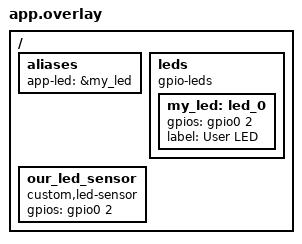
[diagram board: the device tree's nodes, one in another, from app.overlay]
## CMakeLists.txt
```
cmake_minimum_required(VERSION 3.20.0)

find_package(Zephyr REQUIRED)
project(my_zephyr_app)

target_sources(app PRIVATE src/main.c src/shell_cmds.c)
```

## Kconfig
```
# ============================================================================
# Application Kconfig — LED Subsystem
# ============================================================================
# This file defines the configuration space for the course application's
# LED heartbeat subsystem.  It demonstrates:
#   • A top-level menu entry
#   • A conditional block (`if … endif`)
#   • A `choice` with mutually-exclusive options
#   • An `int` symbol with `range`
#   • A `visible if` dependency on a sub-menu (modern Zephyr syntax)
#
# Zephyr's Kconfig auto-discovery will pick up this file because it lives in
# APPLICATION_SOURCE_DIR (i.e. the same directory as CMakeLists.txt).
# ============================================================================

menu "LED Subsystem"

# ---------------------------------------------------------------------------
# Master switch — everything below depends on this symbol.
# ---------------------------------------------------------------------------
config LED_SUBSYSTEM
	bool "Enable LED Subsystem"
	default y
	help
	  Enable the LED heartbeat subsystem.  When disabled, the LED pin is
	  left in its default (high-impedance) state and no GPIO activity occurs.

# ---------------------------------------------------------------------------
# All options below are visible only when the master switch is on.
# ---------------------------------------------------------------------------
if LED_SUBSYSTEM

# ---------------------------------------------------------------------------
# LED operating mode — mutually exclusive choices.
# ---------------------------------------------------------------------------
choice LED_MODE
	prompt "LED operating mode"
	default LED_MODE_BLINK
	help
	  Select how the LED behaves at run-time.

	  BLINK  – periodic toggle (heartbeat).
	  SOLID  – continuously driven ON.
	  OFF    – continuously driven OFF.

config LED_MODE_BLINK
	bool "Blink (heartbeat)"
	help
	  Toggle the LED at the period defined by APP_HEARTBEAT_PERIOD_MS.

config LED_MODE_SOLID
	bool "Solid ON"
	help
	  Drive the LED GPIO active-high and keep it on indefinitely.

config LED_MODE_OFF
	bool "Off"
	help
	  Drive the LED GPIO inactive and keep it off indefinitely.

endchoice

# ---------------------------------------------------------------------------
# Tuning options — only relevant when the mode is BLINK.
# ---------------------------------------------------------------------------
menu "Blink Tuning"
	visible if LED_MODE_BLINK

config APP_HEARTBEAT_PERIOD_MS
	int "Heartbeat period (ms)"
	default 500
	range 100 2000
	help
	  Blink period in milliseconds.  The value is clamped to the range
	  [100, 2000] to prevent eye-strain (too fast) or unresponsiveness
	  (too slow).

endmenu

# ---------------------------------------------------------------------------
# Diagnostics options — visible whenever the subsystem is enabled.
# ---------------------------------------------------------------------------
menu "Diagnostics"
	visible if LED_SUBSYSTEM

config LED_LOG_VERBOSE
	bool "Verbose LED logging"
	default n
	help
	  Log every LED state change to the console.  Useful for verifying that
	  the chosen mode and period are actually being applied at run-time.

endmenu

endif # LED_SUBSYSTEM

endmenu

# ---------------------------------------------------------------------------
# Pull in the full Zephyr Kconfig tree so that standard symbols (GPIO, LOG,
# etc.) are defined and can be referenced from prj.conf / defconfig files.
# ---------------------------------------------------------------------------
source "Kconfig.zephyr"
```

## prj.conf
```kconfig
# ============================================================================
# Project Configuration — Lecture 4 (Devicetree Overlay + Kconfig)
# ============================================================================
# This file overrides default values defined in the application Kconfig
# (app/Kconfig) and in Zephyr's own Kconfig tree.
# ============================================================================

# ---------------------------------------------------------------------------
# Zephyr base requirements
# ---------------------------------------------------------------------------
CONFIG_GPIO=y
CONFIG_LOG=y

# ---------------------------------------------------------------------------
# Heartbeat period (ms)
# Default in Kconfig is 500; range enforced: 100 .. 2000 ms.
# Change this value and rebuild to verify the LED blink speed changes.
# ---------------------------------------------------------------------------
CONFIG_APP_HEARTBEAT_PERIOD_MS=500
CONFIG_SENSOR=y
CONFIG_OUR_LED_SENSOR=y

# ---------------------------------------------------------------------------
# Shell subsystem (L7)
# ---------------------------------------------------------------------------
CONFIG_SHELL=y
CONFIG_SHELL_CMDS=y
CONFIG_SHELL_TAB=y
CONFIG_SHELL_TAB_AUTOCOMPLETION=y
CONFIG_SHELL_HISTORY=y
CONFIG_SHELL_LOG_BACKEND=y
CONFIG_SHELL_BACKEND_SERIAL=y
```

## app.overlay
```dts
/ {
    aliases {
        app-led = &my_led;
    };

    leds {
        compatible = "gpio-leds";
        my_led: led_0 {
            gpios = <&gpio0 2 GPIO_ACTIVE_HIGH>;
            label = "User LED";
        };
    };

    our_led_sensor: our_led_sensor {
        compatible = "custom,led-sensor";
        gpios = <&gpio0 2 GPIO_ACTIVE_HIGH>;
        status = "okay";
    };
};
```

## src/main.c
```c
#include <zephyr/device.h>
#include <zephyr/devicetree.h>
#include <zephyr/drivers/sensor.h>
#include <zephyr/kernel.h>
#include <zephyr/logging/log.h>

/* Task 2 custom extension API header */
#include <drivers/sensor/our_led_sensor.h>

LOG_MODULE_REGISTER(main, LOG_LEVEL_INF);

#define LED_SENSOR_NODE DT_COMPAT_GET_ANY_STATUS_OKAY(custom_led_sensor)

int main(void)
{
	const struct device *dev = DEVICE_DT_GET(LED_SENSOR_NODE);

	if (!device_is_ready(dev)) {
		LOG_ERR("LED sensor device not ready");
		return 0;
	}

	LOG_INF("LED sensor ready");

	/* Task 1: fetch = ON, channel_get = OFF */
	sensor_sample_fetch(dev);
	LOG_INF("LED should be ON after sample_fetch");
	k_msleep(1000);

	sensor_channel_get(dev, SENSOR_CHAN_ALL, NULL);
	LOG_INF("LED should be OFF after channel_get");
	k_msleep(1000);

	/* Task 2: call custom extension API */
	our_led_sensor_toggle(dev);
	LOG_INF("LED toggled via custom API");

	while (1) {
		k_msleep(1000);
	}

	return 0;
}
```

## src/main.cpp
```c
#include <zephyr/drivers/gpio.h>
#include <zephyr/kernel.h>
#include <zephyr/logging/log.h>

/* ==========================================================================
 * Build-time configuration — generated from Kconfig
 * ========================================================================== */
#define SLEEP_TIME_MS CONFIG_APP_HEARTBEAT_PERIOD_MS

/* The devicetree node identifier for the "app-led" alias. */
#define LED_NODE DT_ALIAS(app_led)

/* Compile-time safety: ensure the alias exists in the merged devicetree */
#if !DT_NODE_HAS_STATUS(LED_NODE, okay)
#error "Alias app-led is missing or not enabled"
#endif

/* GPIO specification extracted from devicetree */
static const struct gpio_dt_spec led = GPIO_DT_SPEC_GET(LED_NODE, gpios);

LOG_MODULE_REGISTER(main, LOG_LEVEL_INF);

/* ========================================================================== */
int main(void)
{
    bool led_state = true;

    /* ------------------------------------------------------------------
     * GPIO initialisation
     * ------------------------------------------------------------------ */
    if (!gpio_is_ready_dt(&led)) {
        LOG_ERR("LED GPIO device not ready");
        return 0;
    }

    if (gpio_pin_configure_dt(&led, GPIO_OUTPUT_ACTIVE) < 0) {
        LOG_ERR("Failed to configure LED GPIO");
        return 0;
    }

    /* Print extracted devicetree properties as evidence */
    LOG_INF("DT alias app-led -> node=%s, label=%s, pin=%u",
            DT_NODE_FULL_NAME(LED_NODE), DT_PROP(LED_NODE, label), led.pin);

    /* ------------------------------------------------------------------
     * Heartbeat loop
     * ------------------------------------------------------------------ */
    LOG_INF("Heartbeat LED (period=%d ms)", SLEEP_TIME_MS);

    while (1) {
        if (gpio_pin_toggle_dt(&led) < 0) {
            LOG_ERR("GPIO toggle failed");
            return 0;
        }

        led_state = !led_state;
        LOG_INF("LED state: %s", led_state ? "ON" : "OFF");

        k_msleep(SLEEP_TIME_MS);
    }
}
```

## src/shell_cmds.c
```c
/**
 * L7 Shell Commands for our_led_sensor driver
 */

#include <zephyr/device.h>
#include <zephyr/devicetree.h>
#include <zephyr/drivers/sensor.h>
#include <zephyr/shell/shell.h>

#include <drivers/sensor/our_led_sensor.h>

#define LED_SENSOR_NODE DT_COMPAT_GET_ANY_STATUS_OKAY(custom_led_sensor)

/* --------------------------------------------------------------------------
 * Shared device helper
 * -------------------------------------------------------------------------- */
static const struct device *get_sensor_dev(void)
{
	const struct device *dev = DEVICE_DT_GET(LED_SENSOR_NODE);

	if (!device_is_ready(dev)) {
		return NULL;
	}
	return dev;
}

/* --------------------------------------------------------------------------
 * sensor fetch -- calls sensor_sample_fetch(dev)
 * -------------------------------------------------------------------------- */
static int cmd_sensor_fetch(const struct shell *sh, size_t argc, char **argv)
{
	ARG_UNUSED(argc);
	ARG_UNUSED(argv);

	const struct device *dev = get_sensor_dev();

	if (dev == NULL) {
		shell_error(sh, "Sensor device not ready");
		return -ENODEV;
	}

	int ret = sensor_sample_fetch(dev);

	if (ret != 0) {
		shell_error(sh, "sensor_sample_fetch failed: %d", ret);
		return ret;
	}

	shell_print(sh, "sensor_sample_fetch OK — LED should be ON");
	return 0;
}

/* --------------------------------------------------------------------------
 * sensor read -- calls sensor_channel_get(dev, SENSOR_CHAN_ALL, NULL)
 * -------------------------------------------------------------------------- */
static int cmd_sensor_read(const struct shell *sh, size_t argc, char **argv)
{
	ARG_UNUSED(argc);
	ARG_UNUSED(argv);

	const struct device *dev = get_sensor_dev();

	if (dev == NULL) {
		shell_error(sh, "Sensor device not ready");
		return -ENODEV;
	}

	int ret = sensor_channel_get(dev, SENSOR_CHAN_ALL, NULL);

	if (ret != 0) {
		shell_error(sh, "sensor_channel_get failed: %d", ret);
		return ret;
	}

	shell_print(sh, "sensor_channel_get OK — LED should be OFF");
	return 0;
}

/* --------------------------------------------------------------------------
 * sensor info -- prints device name and ready state
 * -------------------------------------------------------------------------- */
static int cmd_sensor_info(const struct shell *sh, size_t argc, char **argv)
{
	ARG_UNUSED(argc);
	ARG_UNUSED(argv);

	const struct device *dev = get_sensor_dev();

	shell_print(sh, "Device name : %s", dev ? dev->name : "(null)");
	shell_print(sh, "Ready state : %s", (dev && device_is_ready(dev)) ? "ready" : "not ready");
	return 0;
}

/* --------------------------------------------------------------------------
 * sensor set <value> -- calls our_led_sensor_toggle() when value == toggle
 *                         or controls LED directly with 0/1
 * -------------------------------------------------------------------------- */
static int cmd_sensor_set(const struct shell *sh, size_t argc, char **argv)
{
	if (argc != 2) {
		shell_error(sh, "Usage: sensor set <0|1|toggle>");
		return -EINVAL;
	}

	const struct device *dev = get_sensor_dev();

	if (dev == NULL) {
		shell_error(sh, "Sensor device not ready");
		return -ENODEV;
	}

	if (strcmp(argv[1], "toggle") == 0) {
		int ret = our_led_sensor_toggle(dev);
		if (ret != 0) {
			shell_error(sh, "our_led_sensor_toggle failed: %d", ret);
			return ret;
		}
		shell_print(sh, "LED toggled via custom API");
		return 0;
	}

	/* Expect numeric 0 or 1 */
	char *endptr;
	long val = strtol(argv[1], &endptr, 10);

	if ((*endptr != '\0') || (val != 0 && val != 1)) {
		shell_error(sh, "Invalid argument: '%s'. Expected 0, 1, or toggle.", argv[1]);
		return -EINVAL;
	}

	/* Use the public sensor API to set LED state */
	int ret;

	if (val == 1) {
		ret = sensor_sample_fetch(dev);
	} else {
		ret = sensor_channel_get(dev, SENSOR_CHAN_ALL, NULL);
	}

	if (ret != 0) {
		shell_error(sh, "Failed to set LED state: %d", ret);
		return ret;
	}

	shell_print(sh, "LED set to %s", val ? "ON" : "OFF");
	return 0;
}

/* --------------------------------------------------------------------------
 * Subcommand table
 * -------------------------------------------------------------------------- */
SHELL_STATIC_SUBCMD_SET_CREATE(
	sub_sensor,
	SHELL_CMD(fetch, NULL, "Call sensor_sample_fetch() (turns LED ON)", cmd_sensor_fetch),
	SHELL_CMD(read, NULL, "Call sensor_channel_get() (turns LED OFF)", cmd_sensor_read),
	SHELL_CMD(info, NULL, "Show sensor device name and ready state", cmd_sensor_info),
	SHELL_CMD(set, NULL, "Set LED: sensor set <0|1|toggle>", cmd_sensor_set),
	SHELL_SUBCMD_SET_END);

/* --------------------------------------------------------------------------
 * Root command registration
 * -------------------------------------------------------------------------- */
SHELL_CMD_REGISTER(sensor, &sub_sensor, "Custom LED-sensor shell commands", NULL);
```
